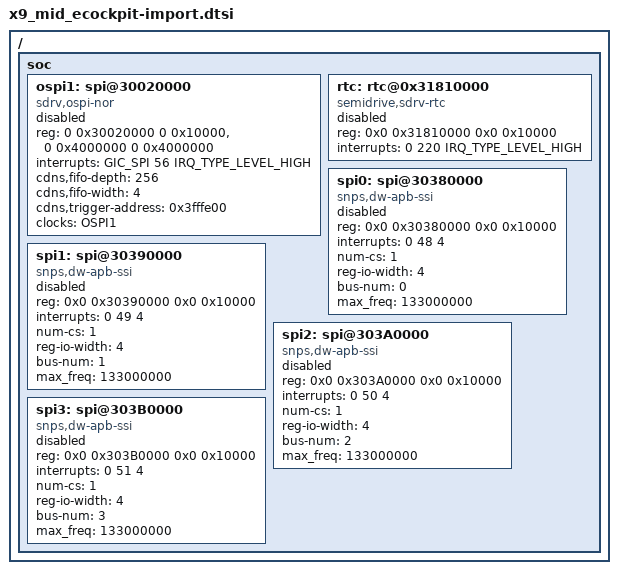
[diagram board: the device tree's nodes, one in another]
/*
* Semidrive X9 platform DTS file
*
* Copyright (C) 2019, Semidrive  Communications Inc.
*
* This file is licensed under a dual GPLv2 or X11 license.
*/

/*Note: add safety/rtc imported resources here!*/

/ {
	soc{

		ospi1: spi@30020000 {
			compatible = "sdrv,ospi-nor";
			#address-cells = <1>;
			#size-cells = <0>;
			reg = <0 0x30020000 0 0x10000>,
				<0 0x4000000 0 0x4000000>;
			interrupts = <GIC_SPI 56 IRQ_TYPE_LEVEL_HIGH>;
			cdns,fifo-depth = <256>;
			cdns,fifo-width = <4>;
			cdns,trigger-address = <0x3fffe00>;
			clocks = <&OSPI1>;
			status = "disabled";
		};

		rtc: rtc@0x31810000 {
			compatible = "semidrive,sdrv-rtc";
			reg = <0x0 0x31810000 0x0 0x10000>;
			interrupts = <0 220 IRQ_TYPE_LEVEL_HIGH>;
			status = "disabled";
		};

		spi0: spi@30380000 { /* physical spi num is 1 */
			compatible = "snps,dw-apb-ssi";
			reg = <0x0 0x30380000 0x0 0x10000>;
			interrupts = <0 48 4>;
			num-cs = <1>;
			reg-io-width = <4>;
			bus-num = <0>;
			#address-cells = <1>;
			#size-cells = <0>;
			max_freq = <133000000>;
			status = "disabled";
		};

		spi1: spi@30390000 { /* physical spi num is 2 */
			compatible = "snps,dw-apb-ssi";
			reg = <0x0 0x30390000 0x0 0x10000>;
			interrupts = <0 49 4>;
			num-cs = <1>;
			reg-io-width = <4>;
			bus-num = <1>;
			#address-cells = <1>;
			#size-cells = <0>;
			max_freq = <133000000>;
			status = "disabled";
		};

		spi2: spi@303A0000 { /* physical spi num is 3 */
			compatible = "snps,dw-apb-ssi";
			reg = <0x0 0x303A0000 0x0 0x10000>;
			interrupts = <0 50 4>;
			num-cs = <1>;
			reg-io-width = <4>;
			bus-num = <2>;
			#address-cells = <1>;
			#size-cells = <0>;
			max_freq = <133000000>;
			status = "disabled";
		};

		spi3: spi@303B0000 { /* physical spi num is 4 */
			compatible = "snps,dw-apb-ssi";
			reg = <0x0 0x303B0000 0x0 0x10000>;
			interrupts = <0 51 4>;
			num-cs = <1>;
			reg-io-width = <4>;
			bus-num = <3>;
			#address-cells = <1>;
			#size-cells = <0>;
			max_freq = <133000000>;
			status = "disabled";
		};
	};
};
